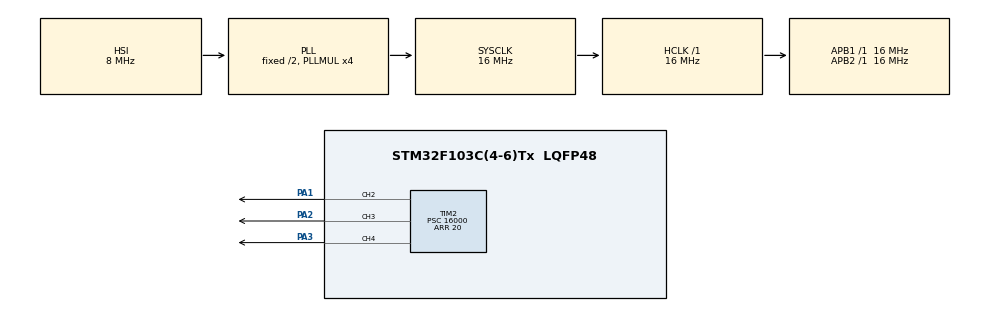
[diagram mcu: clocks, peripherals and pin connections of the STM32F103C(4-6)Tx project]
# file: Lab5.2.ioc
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Mcu.Family=STM32F1
TIM2.Channel-PWM\ Generation4\ CH4=TIM_CHANNEL_4
TIM2.Channel-PWM\ Generation2\ CH2=TIM_CHANNEL_2
VP_SYS_VS_ND.Mode=No_Debug
RCC.SYSCLKSource=RCC_SYSCLKSOURCE_PLLCLK
ProjectManager.StackSize=0x400
SH.S_TIM2_CH2.0=TIM2_CH2,PWM Generation2 CH2
ProjectManager.TargetToolchain=STM32CubeIDE
TIM2.Pulse-PWM\ Generation3\ CH3=1
RCC.HCLKFreq_Value=16000000
RCC.APB2TimFreq_Value=16000000
TIM3.Period=200
RCC.USBFreq_Value=16000000
PA1.Signal=S_TIM2_CH2
RCC.AHBFreq_Value=16000000
board=custom
RCC.PLLMUL=RCC_PLL_MUL4
NVIC.TIM3_IRQn=true\:0\:0\:false\:true\:true\:1\:true\:true
RCC.APB2Freq_Value=16000000
SH.S_TIM2_CH3.0=TIM2_CH3,PWM Generation3 CH3
TIM3.Prescaler=8000
TIM2.Channel-PWM\ Generation3\ CH3=TIM_CHANNEL_3
TIM2.Period=20
Mcu.Name=STM32F103C(4-6)Tx
PA2.Signal=S_TIM2_CH3
RCC.SYSCLKFreq_VALUE=16000000
Mcu.Package=LQFP48
TIM2.Prescaler=16000
ProjectManager.HeapSize=0x200
SH.S_TIM2_CH4.0=TIM2_CH4,PWM Generation4 CH4
TIM2.Pulse-PWM\ Generation2\ CH2=3
NVIC.PriorityGroup=NVIC_PRIORITYGROUP_4
RCC.APB1TimFreq_Value=16000000
TIM2.Pulse-PWM\ Generation4\ CH4=2.5
TIM3.TIM_MasterOutputTrigger=TIM_TRGO_UPDATE
RCC.APB1Freq_Value=16000000
VP_TIM3_VS_ClockSourceINT.Mode=Internal
PA3.Signal=S_TIM2_CH4

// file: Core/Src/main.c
/* USER CODE BEGIN Header */
/**
  ******************************************************************************
  * @file           : main.c
  * @brief          : Main program body
  ******************************************************************************
  * @attention
  *
  * <h2><center>&copy; Copyright (c) 2021 STMicroelectronics.
  * All rights reserved.</center></h2>
  *
  * This software component is licensed by ST under BSD 3-Clause license,
  * the "License"; You may not use this file except in compliance with the
  * License. You may obtain a copy of the License at:
  *                        opensource.org/licenses/BSD-3-Clause
  *
  ******************************************************************************
  */
/* USER CODE END Header */
#include "main.h"
#include "tim.h"
#include "gpio.h"

/* USER CODE BEGIN Includes */
#include "stdbool.h"
/* USER CODE END Includes */

/* USER CODE BEGIN PM */
short getNextPwmPuls(short pwm);
/* USER CODE END PM */

/* USER CODE BEGIN PV */
short pwmPulse = 0;
short pwmPulse2 = 0;
/* USER CODE END PV */

void SystemClock_Config(void);
static void MX_NVIC_Init(void);

int main(void)
{

  /* MCU Configuration--------------------------------------------------------*/

  /* Reset of all peripherals, Initializes the Flash interface and the Systick. */
  HAL_Init();

  /* Configure the system clock */
  SystemClock_Config();

  /* Initialize all configured peripherals */
  MX_GPIO_Init();
  MX_TIM2_Init();
  MX_TIM3_Init();

  /* Initialize interrupts */
  MX_NVIC_Init();
  /* USER CODE BEGIN 2 */
  HAL_TIM_PWM_Start(&htim2, TIM_CHANNEL_2);
  HAL_TIM_PWM_Start(&htim2, TIM_CHANNEL_3);
  HAL_TIM_PWM_Start(&htim2, TIM_CHANNEL_4);
  HAL_TIM_Base_Start(&htim3);
  __HAL_TIM_ENABLE_IT(&htim3, TIM_IT_UPDATE );
  /* USER CODE END 2 */

  /* Infinite loop */
  while (1)
  {

	  pwmPulse = getNextPwmPuls(pwmPulse);

	  __HAL_TIM_SetCompare(&htim2, TIM_CHANNEL_4, pwmPulse);

	  HAL_Delay(250);

	  __HAL_TIM_SetCompare(&htim2, TIM_CHANNEL_3, pwmPulse);

	  HAL_Delay(250);

	  __HAL_TIM_SetCompare(&htim2, TIM_CHANNEL_4, getNextPwmPuls(pwmPulse));

  }
}

void SystemClock_Config(void)
{
  RCC_OscInitTypeDef RCC_OscInitStruct = {0};
  RCC_ClkInitTypeDef RCC_ClkInitStruct = {0};

  /** Initializes the RCC Oscillators according to the specified parameters
  * in the RCC_OscInitTypeDef structure.
  */
  RCC_OscInitStruct.OscillatorType = RCC_OSCILLATORTYPE_HSI;
  RCC_OscInitStruct.HSIState = RCC_HSI_ON;
  RCC_OscInitStruct.HSICalibrationValue = RCC_HSICALIBRATION_DEFAULT;
  RCC_OscInitStruct.PLL.PLLState = RCC_PLL_ON;
  RCC_OscInitStruct.PLL.PLLSource = RCC_PLLSOURCE_HSI_DIV2;
  RCC_OscInitStruct.PLL.PLLMUL = RCC_PLL_MUL4;
  if (HAL_RCC_OscConfig(&RCC_OscInitStruct) != HAL_OK)
  {
    Error_Handler();
  }
  /** Initializes the CPU, AHB and APB buses clocks
  */
  RCC_ClkInitStruct.ClockType = RCC_CLOCKTYPE_HCLK|RCC_CLOCKTYPE_SYSCLK
                              |RCC_CLOCKTYPE_PCLK1|RCC_CLOCKTYPE_PCLK2;
  RCC_ClkInitStruct.SYSCLKSource = RCC_SYSCLKSOURCE_PLLCLK;
  RCC_ClkInitStruct.AHBCLKDivider = RCC_SYSCLK_DIV1;
  RCC_ClkInitStruct.APB1CLKDivider = RCC_HCLK_DIV1;
  RCC_ClkInitStruct.APB2CLKDivider = RCC_HCLK_DIV1;

  if (HAL_RCC_ClockConfig(&RCC_ClkInitStruct, FLASH_LATENCY_0) != HAL_OK)
  {
    Error_Handler();
  }
}

/**
  * @brief NVIC Configuration.
  * @retval None
  */
static void MX_NVIC_Init(void)
{
  /* TIM3_IRQn interrupt configuration */
  HAL_NVIC_SetPriority(TIM3_IRQn, 0, 0);
  HAL_NVIC_EnableIRQ(TIM3_IRQn);
}

/* USER CODE BEGIN 4 */

short getNextPwmPuls(short pwm)
{
	if(pwmPulse == 19)
	{
		return 1;
	}
	else
	{
		return 19;
	}
}
void HAL_TIM_PeriodElapsedCallback(TIM_HandleTypeDef *htim)
{
	if(htim->Instance == TIM3)
	{
		__HAL_TIM_SetCompare(&htim2, TIM_CHANNEL_3, pwmPulse2);

		if(pwmPulse2 < 19)
		{
			pwmPulse2+=1;
		}
		else
		{
			pwmPulse2 -= 0;
		}
	}
}
/* USER CODE END 4 */

void Error_Handler(void)
{
  __disable_irq();
  while (1)
  {
  }
}

/************************ (C) COPYRIGHT STMicroelectronics *****END OF FILE****/
